# STM32H7R register map
File version: 1.4
CPU: CM7 r0p1, little endian, MPU, FPU, 4 interrupt priority bits
Registers are 32-bit, read-write, reset 0x0 unless marked. A register's access mark holds for its fields unless they carry their own. Offsets are from the block's base; [hi:lo] are bit positions; {n}, {i} and the like mark numbered series; 'fields as' and 'values as' point back to an identical list.

## HASH — Hash processor
Base 0x48020400
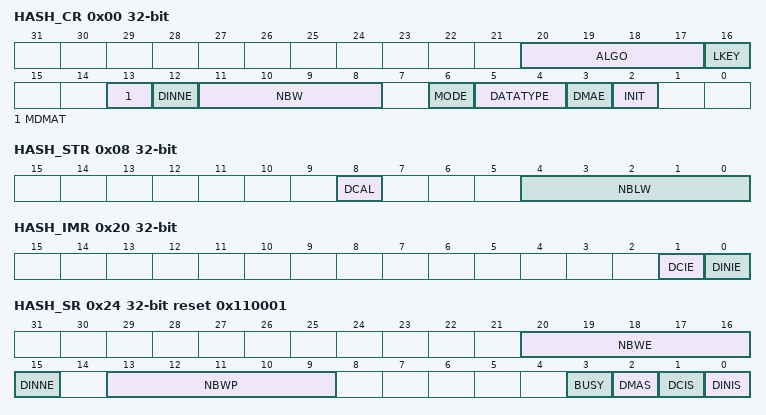
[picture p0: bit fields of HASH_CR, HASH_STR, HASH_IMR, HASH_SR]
0x00 HASH_CR access per field — HASH control register
  [20:17] ALGO rw — Algorithm selection These bits select the hash algorithm: This selection is only taken into account when the INIT bit is set. Changing this bitfield during a computation has no effect. When the ALGO bitfield is updated and INIT bit is set, NBWE in HASH_SR is automatically updated to 0x11.
    0=SHA-1; 1=FIELD Reserved; 2=SHA2-224; 3=SHA2-256; 12=SHA2-384; 13=SHA2-512/224; 14=SHA2-512/256; 15=SHA2-512
  [16] LKEY rw — Long key selection The application must set this bit if the HMAC key is greater than the block size corresponding to the hash algorithm (see Table 280: Information on supported hash algorithms for details). For example the block size is 64 bytes for SHA2-256. This selection is only taken into account when the INIT and MODE bits are set (HMAC mode selected). Changing this bit during a computation has no effect.
    0=HMAC key is shorter or equal to the block size (short key). The actual key value written in HASH_DIN is used during the HMAC computation.; 1=HMAC key is longer than the block size (long key). The hash of the key is used instead of the real key during the HMAC computation.
  [13] MDMAT rw — Multiple DMA transfers This bit is set when hashing large files when multiple DMA transfers are needed.
    0=DCAL is automatically set at the end of a DMA transfer; 1=DCAL is not automatically set at the end of a DMA transfer
  [12] DINNE ro — DIN not empty Refer to DINNE bit of HASH_SR for a description of DINNE bit. This bit is read-only.
  [11:8] NBW ro — Number of words already pushed Refer to NBWP[3:0] bitfield of HASH_SR for a description of NBW[3:0] bitfield. This bit is read-only.
  [6] MODE rw — Mode selection This bit selects the normal or the keyed HMAC mode for the selected algorithm: This selection is only taken into account when the INIT bit is set. Changing this bit during a computation has no effect.
    0=Hash mode selected; 1=HMAC mode selected. LKEY bit must be set if the key being used is longer than the algorithm block size.
  [5:4] DATATYPE rw — Data type selection This bitfield defines the format of the data entered into the HASH_DIN register:
    0=32-bit data. The data written into HASH_DIN are directly used by the HASH processing, without reordering.; 1=16-bit data or half-word. The data written into HASH_DIN are considered as two half-words, and are swapped before being used by the HASH processing.; 2=8-bit data or bytes. The data written into HASH_DIN are considered as four bytes, and are swapped before being used by the HASH processing.; 3=bit data or bit string. The data written into HASH_DIN are considered as 32 bits (1st bit of the string at position 0), and are swapped before being used by the HASH processing (1st bit of the string at position 31).
  [3] DMAE rw — DMA enable After this bit is set, it is cleared by hardware while the last data of the message is written into the hash processor. Setting this bit to 0 while a DMA transfer is ongoing does not abort the current transfer. Instead, the DMA interface of the HASH remains internally enabled until the transfer is completed or INIT is written to 1. Setting INIT bit to 1 does not clear DMAE bit.
    0=DMA transfers disabled; 1=DMA transfers enabled. A DMA request is sent as soon as the hash core is ready to receive data.
  [2] INIT rw — Initialize message digest calculation Writing this bit to 1 resets the hash processor core, so that the HASH is ready to compute the message digest of a new message. Writing this bit to 0 has no effect. Reading this bit always returns 0.
0x04 HASH_DIN wo — HASH data input register
  [31:0] DATAIN — Data input Writing this register pushes the current register content into the FIFO, and the register takes the new value presented on the AHB bus. Reading this register returns zeros.
0x08 HASH_STR — HASH start register
  [8] DCAL — Digest calculation Writing this bit to 1 starts the message padding using the previously written value of NBLW, and starts the calculation of the final message digest with all the data words written to the input FIFO since the INIT bit was last written to 1. Reading this bit returns 0.
  [4:0] NBLW — Number of valid bits in the last word When the last word of the message bit string is written to HASH_DIN register, the hash processor takes only the valid bits, specified as below, after internal data swapping: ... The above mechanism is valid only if DCAL = 0. If NBLW bits are written while DCAL is set to 1, the NBLW bitfield remains unchanged. In other words it is not possible to configure NBLW and set DCAL at the same time. Reading NBLW bits returns the last value written to NBLW.
    0=All the 32 bits of the last data written are valid message bits, that is M[31:0]; 1=Only one bit of the last data written (after swapping) is valid, that is M[0]; 2=Only two bits of the last data written (after swapping) are valid, that is M[1:0]; 3=Only three bits of the last data written (after swapping) are valid that is M[2:0]; 31=Only 31 bits of the last data written (after swapping) are valid that is M[30:0]
{0xC+4i} HASH_HRA{i} ro (i=0..4) — HASH aliased digest register {i}
  [31:0] H{i} — Hash data x Refer to Section 34.7.4: HASH digest registers introduction.
0x20 HASH_IMR — HASH interrupt enable register
  [1] DCIE — Digest calculation completion interrupt enable
    0=Digest calculation completion interrupt disabled; 1=Digest calculation completion interrupt enabled
  [0] DINIE — Data input interrupt enable
    0=Data input interrupt disabled; 1=Data input interrupt enabled
0x24 HASH_SR access per field reset 0x110001 — HASH status register
  [20:16] NBWE ro — Number of words expected This bitfield reflects the number of words in the message that must be pushed into the FIFO to trigger a partial computation. NBWE is decremented by 1 when a write access is performed to the HASH_DIN register. NBWE is set to the expected block size +1 in words (0x11) when INIT bit is set in HASH_CR. It is set to the expected block size (0x10) when the partial digest calculation ends.
  [15] DINNE ro — DIN not empty This bit is set when the HASH_DIN register holds valid data (that is after being written at least once). It is cleared when either the INIT bit (initialization) or the DCAL bit (completion of the previous message processing) is written to 1.
    0=No data are present in the data input buffer; 1=The input buffer contains at least one word of data
  [13:9] NBWP ro — Number of words already pushed This bitfield is the exact number of words in the message that have already been pushed into the FIFO. NBWP is incremented by 1 when a write access is performed to the HASH_DIN register. When a digest calculation starts, NBWP is updated to NBWP- block size (in words), and NBWP goes to zero when the INIT bit is written to 1.
  [3] BUSY ro — Busy bit
    0=No block is currently being processed; 1=The hash core is processing a block of data
  [2] DMAS ro — DMA Status This bit provides information on the DMA interface activity. It is set with DMAE and cleared when DMAE = 0 and no DMA transfer is ongoing. No interrupt is associated with this bit.
    0=DMA interface is disabled (DMAE = 0) and no transfer is ongoing; 1=DMA interface is enabled (DMAE = 1) or a transfer is ongoing
  [1] DCIS rw — Digest calculation completion interrupt status This bit is set by hardware when a digest becomes ready (the whole message has been processed). It is cleared by writing it to 0 or by writing the INIT bit to 1 in the HASH_CR register.
    0=No digest available in the HASH_HRx registers (zeros are returned); 1=Digest calculation complete, a digest is available in the HASH_HRx registers. An interrupt is generated if the DCIE bit is set in the HASH_IMR register.
  [0] DINIS rw — Data input interrupt status This bit is set by hardware when the FIFO is ready to get a new block (16 locations are free). It is cleared by writing it to 0 or by writing the HASH_DIN register. When DINIS = 0, HASH_CSRx registers reads as zero.
    0=Less than 16 locations are free in the input buffer; 1=A new block can be entered into the input buffer. An interrupt is generated if the DINIE bit is set in the HASH_IMR register.
{0xF8+4i} HASH_CSR{i} (i=0..102) — HASH context swap register {i}
  [31:0] CS{i} — Context swap x Refer to Section 34.7.7: HASH context swap registers introduction.
{0x310+4i} HASH_HR{i} ro (i=0..4) — HASH digest register {i}
  fields as HASH_HRA0
{0x310+4i} HASH_HR{i} ro (i=5..15) — HASH supplementary digest register {i}
  fields as HASH_HRA0
